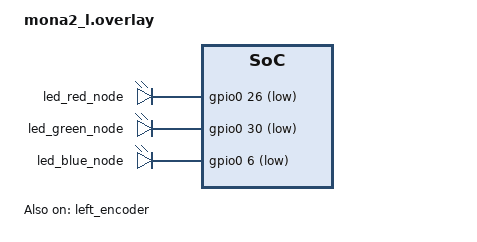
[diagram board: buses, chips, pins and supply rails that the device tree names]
#include "mona2.dtsi"

&kscan0 {
        col-gpios
            = <&xiao_d 10 GPIO_ACTIVE_HIGH>
            , <&xiao_d 9 GPIO_ACTIVE_HIGH> 
            , <&xiao_d 8 GPIO_ACTIVE_HIGH> 
            , <&xiao_d 7 GPIO_ACTIVE_HIGH> 
            , <&gpio0 10 GPIO_ACTIVE_HIGH>
            , <&gpio0 9 GPIO_ACTIVE_HIGH>
            ;
};

&left_encoder {
    status = "okay";
};
/ {
    aliases {
        led-red   = &led_red_node;
        led-green = &led_green_node;
        led-blue  = &led_blue_node;
    };

    leds {
        compatible = "gpio-leds";
        led_red_node: led_red {
            gpios = <&gpio0 26 GPIO_ACTIVE_LOW>;
        };
        led_green_node: led_green {
            gpios = <&gpio0 30 GPIO_ACTIVE_LOW>;
        };
        led_blue_node: led_blue {
            gpios = <&gpio0 6 GPIO_ACTIVE_LOW>;
        };
    };
};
